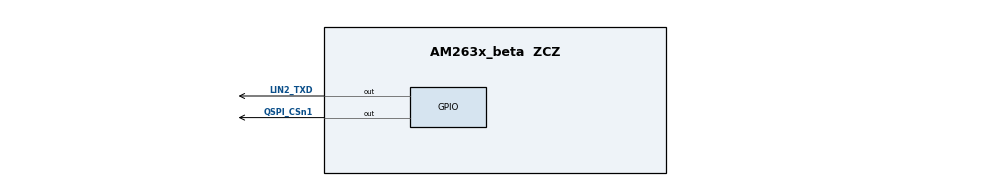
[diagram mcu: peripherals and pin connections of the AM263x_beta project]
/**
 * @cliArgs --device "AM263x_beta" --package "ZCZ" --part "AM263x" --context "r5fss0-0" --product "MCU_PLUS_SDK@07.03.01"
 * @versions {"tool":"1.10.0+2163"}
 */

/**
 * Import the modules used in this configuration.
 */
const led        = scripting.addModule("/board/led/led", {}, false);
const led1       = led.addInstance();
const led2       = led.addInstance();
const gpio       = scripting.addModule("/drivers/gpio/gpio", {}, false);
const gpio1      = gpio.addInstance();
const gpio2      = gpio.addInstance();
const debug_log  = scripting.addModule("/kernel/dpl/debug_log");
const mpu_armv7  = scripting.addModule("/kernel/dpl/mpu_armv7", {}, false);
const mpu_armv71 = mpu_armv7.addInstance();
const mpu_armv72 = mpu_armv7.addInstance();
const mpu_armv73 = mpu_armv7.addInstance();
const mpu_armv74 = mpu_armv7.addInstance();

/**
 * Write custom configuration values to the imported modules.
 */
led1.$name = "CONFIG_LED0";

led2.$name = "CONFIG_LED1";

gpio1.$name                = "CONFIG_GPIO0";
led1.peripheralDriver      = gpio1;
gpio1.pinDir               = "OUTPUT";
gpio1.GPIO.gpioPin.$assign = "QSPI_CSn1";

gpio2.$name                = "CONFIG_GPIO1";
led2.peripheralDriver      = gpio2;
gpio2.pinDir               = "OUTPUT";
gpio2.GPIO.gpioPin.$assign = "LIN2_TXD";

debug_log.enableUartLog            = true;
debug_log.uartLog.$name            = "CONFIG_UART0";
debug_log.uartLog.UART.RXD.$assign = "UART0_RXD";
debug_log.uartLog.UART.TXD.$assign = "UART0_TXD";

mpu_armv71.$name             = "CONFIG_MPU_REGION0";
mpu_armv71.size              = 31;
mpu_armv71.attributes        = "Device";
mpu_armv71.accessPermissions = "Supervisor RD+WR, User RD";
mpu_armv71.allowExecute      = false;

mpu_armv72.$name             = "CONFIG_MPU_REGION1";
mpu_armv72.size              = 15;
mpu_armv72.accessPermissions = "Supervisor RD+WR, User RD";

mpu_armv73.$name             = "CONFIG_MPU_REGION2";
mpu_armv73.baseAddr          = 0x80000;
mpu_armv73.size              = 15;
mpu_armv73.accessPermissions = "Supervisor RD+WR, User RD";

mpu_armv74.$name             = "CONFIG_MPU_REGION3";
mpu_armv74.accessPermissions = "Supervisor RD+WR, User RD";
mpu_armv74.baseAddr          = 0x70000000;
mpu_armv74.size              = 21;

/**
 * Pinmux solution for unlocked pins/peripherals. This ensures that minor changes to the automatic solver in a future
 * version of the tool will not impact the pinmux you originally saw.  These lines can be completely deleted in order to
 * re-solve from scratch.
 */
gpio1.GPIO.$suggestSolution             = "GPIO0";
gpio2.GPIO.$suggestSolution             = "GPIO0";
debug_log.uartLog.UART.$suggestSolution = "UART0";
